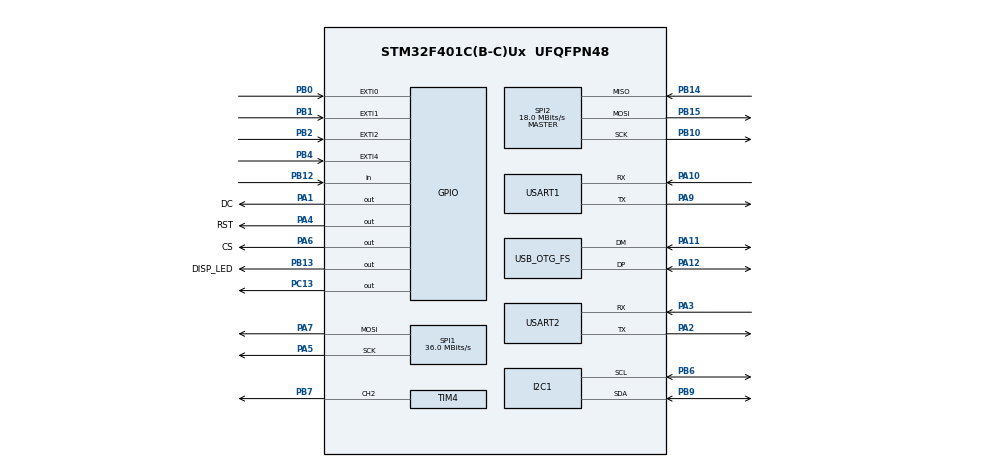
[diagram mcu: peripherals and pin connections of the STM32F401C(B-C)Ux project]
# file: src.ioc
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Dma.Request0=TIM4_CH2
Dma.TIM4_CH2.0.Direction=DMA_MEMORY_TO_PERIPH
Dma.TIM4_CH2.0.FIFOMode=DMA_FIFOMODE_DISABLE
Dma.TIM4_CH2.0.Instance=DMA1_Stream3
Dma.TIM4_CH2.0.MemDataAlignment=DMA_MDATAALIGN_HALFWORD
Dma.TIM4_CH2.0.MemInc=DMA_MINC_ENABLE
Dma.TIM4_CH2.0.Mode=DMA_CIRCULAR
Dma.TIM4_CH2.0.PeriphDataAlignment=DMA_PDATAALIGN_HALFWORD
Dma.TIM4_CH2.0.PeriphInc=DMA_PINC_DISABLE
Dma.TIM4_CH2.0.Priority=DMA_PRIORITY_LOW
Mcu.Family=STM32F4
Mcu.Name=STM32F401C(B-C)Ux
Mcu.Package=UFQFPN48
NVIC.DMA1_Stream3_IRQn=true\:2\:0\:true\:false\:true\:false\:true\:true
NVIC.EXTI0_IRQn=true\:0\:0\:false\:false\:true\:true\:true\:true
NVIC.EXTI1_IRQn=true\:0\:0\:false\:false\:true\:true\:true\:true
NVIC.EXTI2_IRQn=true\:0\:0\:false\:false\:true\:true\:true\:true
NVIC.EXTI4_IRQn=true\:0\:0\:false\:false\:true\:true\:true\:true
NVIC.OTG_FS_IRQn=true\:0\:0\:false\:false\:true\:false\:true\:true
NVIC.PriorityGroup=NVIC_PRIORITYGROUP_4
PA1.GPIO_Label=DC
PA1.GPIO_Speed=GPIO_SPEED_FREQ_HIGH
PA1.Signal=GPIO_Output
PA10.Mode=Asynchronous
PA10.Signal=USART1_RX
PA11.Mode=Device_Only
PA11.Signal=USB_OTG_FS_DM
PA12.Mode=Device_Only
PA12.Signal=USB_OTG_FS_DP
PA13.Mode=Trace_Asynchronous_SW
PA13.Signal=SYS_JTMS-SWDIO
PA14.Mode=Trace_Asynchronous_SW
PA14.Signal=SYS_JTCK-SWCLK
PA2.Mode=Asynchronous
PA2.Signal=USART2_TX
PA3.Mode=Asynchronous
PA3.Signal=USART2_RX
PA4.GPIO_Label=RST
PA4.GPIO_Speed=GPIO_SPEED_FREQ_HIGH
PA4.Signal=GPIO_Output
PA5.Mode=TX_Only_Simplex_Unidirect_Master
PA5.Signal=SPI1_SCK
PA6.GPIO_Label=CS
PA6.GPIO_Speed=GPIO_SPEED_FREQ_HIGH
PA6.Signal=GPIO_Output
PA7.Mode=TX_Only_Simplex_Unidirect_Master
PA7.Signal=SPI1_MOSI
PA9.Mode=Asynchronous
PA9.Signal=USART1_TX
PB0.GPIO_ModeDefaultEXTI=GPIO_MODE_IT_RISING_FALLING
PB0.GPIO_PuPd=GPIO_PULLDOWN
PB0.Signal=GPXTI0
PB1.GPIO_ModeDefaultEXTI=GPIO_MODE_IT_RISING_FALLING
PB1.GPIO_PuPd=GPIO_PULLDOWN
PB1.Signal=GPXTI1
PB10.Mode=Full_Duplex_Master
PB10.Signal=SPI2_SCK
PB12.GPIO_PuPd=GPIO_PULLDOWN
PB12.Signal=GPIO_Input
PB13.GPIO_Label=DISP_LED
PB13.GPIO_PuPd=GPIO_PULLDOWN
PB13.PinState=GPIO_PIN_SET
PB13.Signal=GPIO_Output
PB14.Mode=Full_Duplex_Master
PB14.Signal=SPI2_MISO
PB15.Mode=Full_Duplex_Master
PB15.Signal=SPI2_MOSI
PB2.GPIO_ModeDefaultEXTI=GPIO_MODE_IT_RISING_FALLING
PB2.GPIO_PuPd=GPIO_PULLDOWN
PB2.Signal=GPXTI2
PB3.Mode=Trace_Asynchronous_SW
PB3.Signal=SYS_JTDO-SWO
PB4.GPIO_ModeDefaultEXTI=GPIO_MODE_IT_RISING_FALLING
PB4.GPIO_PuPd=GPIO_PULLDOWN
PB4.Signal=GPXTI4
PB6.Mode=I2C
PB6.Signal=I2C1_SCL
PB7.GPIO_Speed=GPIO_SPEED_FREQ_LOW
PB7.Signal=S_TIM4_CH2
PB9.Mode=I2C
PB9.Signal=I2C1_SDA
PC13-ANTI_TAMP.GPIO_PuPd=GPIO_PULLUP
PC13-ANTI_TAMP.PinState=GPIO_PIN_SET
PC13-ANTI_TAMP.Signal=GPIO_Output
PC14-OSC32_IN.Mode=LSE-External-Oscillator
PC14-OSC32_IN.Signal=RCC_OSC32_IN
PC15-OSC32_OUT.Mode=LSE-External-Oscillator
PC15-OSC32_OUT.Signal=RCC_OSC32_OUT
PH0\ -\ OSC_IN.Mode=HSE-External-Oscillator
PH0\ -\ OSC_IN.Signal=RCC_OSC_IN
PH1\ -\ OSC_OUT.Mode=HSE-External-Oscillator
PH1\ -\ OSC_OUT.Signal=RCC_OSC_OUT
ProjectManager.HeapSize=0x400
ProjectManager.StackSize=0x800
ProjectManager.TargetToolchain=STM32CubeIDE
RCC.48MHZClocksFreq_Value=48000000
RCC.AHBFreq_Value=72000000
RCC.APB1CLKDivider=RCC_HCLK_DIV2
RCC.APB1Freq_Value=36000000
RCC.APB1TimFreq_Value=72000000
RCC.APB2Freq_Value=72000000
RCC.APB2TimFreq_Value=72000000
RCC.CortexFreq_Value=72000000
RCC.HCLKFreq_Value=72000000
RCC.HSE_VALUE=25000000
RCC.HSI_VALUE=16000000
RCC.PLLM=25
RCC.PLLN=144
RCC.PLLQ=3
RCC.SYSCLKFreq_VALUE=72000000
RCC.SYSCLKSource=RCC_SYSCLKSOURCE_PLLCLK
RCC.VCOOutputFreq_Value=144000000
SH.S_TIM4_CH2.0=TIM4_CH2,PWM Generation2 CH2
SPI1.BaudRatePrescaler=SPI_BAUDRATEPRESCALER_2
SPI1.CalculateBaudRate=36.0 MBits/s
SPI1.Direction=SPI_DIRECTION_2LINES
SPI1.Mode=SPI_MODE_MASTER
SPI1.VirtualType=VM_MASTER
SPI2.BaudRatePrescaler=SPI_BAUDRATEPRESCALER_2
SPI2.CalculateBaudRate=18.0 MBits/s
SPI2.Direction=SPI_DIRECTION_2LINES
SPI2.Mode=SPI_MODE_MASTER
SPI2.VirtualType=VM_MASTER
TIM4.Channel-PWM\ Generation2\ CH2=TIM_CHANNEL_2
TIM4.Period=89
USART1.VirtualMode=VM_ASYNC
USART2.VirtualMode=VM_ASYNC
USB_DEVICE.APP_RX_DATA_SIZE=256
USB_DEVICE.APP_TX_DATA_SIZE=256
USB_DEVICE.CLASS_NAME_FS=CDC
USB_DEVICE.VirtualMode=Cdc
USB_DEVICE.VirtualModeFS=Cdc_FS
USB_OTG_FS.VirtualMode=Device_Only
VP_CRC_VS_CRC.Mode=CRC_Activate
VP_USB_DEVICE_VS_USB_DEVICE_CDC_FS.Mode=CDC_FS
board=custom

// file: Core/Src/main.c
/* USER CODE BEGIN Header */
/**
 ******************************************************************************
 * @file           : main.c
 * @brief          : Main program body
 ******************************************************************************
 * @attention
 *
 * Copyright (c) 2022 STMicroelectronics.
 * All rights reserved.
 *
 * This software is licensed under terms that can be found in the LICENSE file
 * in the root directory of this software component.
 * If no LICENSE file comes with this software, it is provided AS-IS.
 *
 ******************************************************************************
 */
/* USER CODE END Header */
#include "main.h"
#include "crc.h"
#include "dma.h"
#include "gpio.h"
#include "i2c.h"
#include "spi.h"
#include "tim.h"
#include "usart.h"
#include "usb_device.h"

/* USER CODE BEGIN Includes */
#include "menu.h"
/* USER CODE END Includes */

void
SystemClock_Config(void);

int
main(void)
{

  /* MCU Configuration--------------------------------------------------------*/

  /* Reset of all peripherals, Initializes the Flash interface and the Systick.
   */
  HAL_Init();

  /* Configure the system clock */
  SystemClock_Config();

  /* Initialize all configured peripherals */
  MX_GPIO_Init();
  MX_CRC_Init();
  MX_I2C1_Init();
  MX_SPI1_Init();
  MX_SPI2_Init();
  MX_TIM4_Init();
  MX_USART1_UART_Init();
  MX_DMA_Init();
  MX_USB_DEVICE_Init();
  MX_USART2_UART_Init();
  /* USER CODE BEGIN 2 */
  Menu_Init();
  /* USER CODE END 2 */

  /* Infinite loop */
  /* USER CODE BEGIN WHILE */
  while (1) {
Menu();
   // HAL_IWDG_Refresh(&hiwdg);

    /* USER CODE END WHILE */

  }
}

void
SystemClock_Config(void)
{
  RCC_OscInitTypeDef RCC_OscInitStruct = { 0 };
  RCC_ClkInitTypeDef RCC_ClkInitStruct = { 0 };

  /** Configure the main internal regulator output voltage
   */
  __HAL_RCC_PWR_CLK_ENABLE();
  __HAL_PWR_VOLTAGESCALING_CONFIG(PWR_REGULATOR_VOLTAGE_SCALE2);

  /** Initializes the RCC Oscillators according to the specified parameters
  * in the RCC_OscInitTypeDef structure.
  */
  RCC_OscInitStruct.OscillatorType = RCC_OSCILLATORTYPE_HSE;
  RCC_OscInitStruct.HSEState = RCC_HSE_ON;
  RCC_OscInitStruct.PLL.PLLState = RCC_PLL_ON;
  RCC_OscInitStruct.PLL.PLLSource = RCC_PLLSOURCE_HSE;
  RCC_OscInitStruct.PLL.PLLM = 25;
  RCC_OscInitStruct.PLL.PLLN = 144;
  RCC_OscInitStruct.PLL.PLLP = RCC_PLLP_DIV2;
  RCC_OscInitStruct.PLL.PLLQ = 3;
  if (HAL_RCC_OscConfig(&RCC_OscInitStruct) != HAL_OK) {
    Error_Handler();
  }

  /** Initializes the CPU, AHB and APB buses clocks
   */
  RCC_ClkInitStruct.ClockType = RCC_CLOCKTYPE_HCLK | RCC_CLOCKTYPE_SYSCLK |
                                RCC_CLOCKTYPE_PCLK1 | RCC_CLOCKTYPE_PCLK2;
  RCC_ClkInitStruct.SYSCLKSource = RCC_SYSCLKSOURCE_PLLCLK;
  RCC_ClkInitStruct.AHBCLKDivider = RCC_SYSCLK_DIV1;
  RCC_ClkInitStruct.APB1CLKDivider = RCC_HCLK_DIV2;
  RCC_ClkInitStruct.APB2CLKDivider = RCC_HCLK_DIV1;

  if (HAL_RCC_ClockConfig(&RCC_ClkInitStruct, FLASH_LATENCY_2) != HAL_OK) {
    Error_Handler();
  }
}

void
Error_Handler(void)
{
  __disable_irq();
  while (1) {
  }
}

#ifdef USE_FULL_ASSERT
/**
 * @brief  Reports the name of the source file and the source line number
 *         where the assert_param error has occurred.
 * @param  file: pointer to the source file name
 * @param  line: assert_param error line source number
 * @retval None
 */
void
assert_failed(uint8_t* file, uint32_t line)
{
  /* USER CODE BEGIN 6 */
  /* User can add his own implementation to report the file name and line
     number,
     ex: printf("Wrong parameters value: file %s on line %d\r\n", file, line) */
  /* USER CODE END 6 */
}
#endif /* USE_FULL_ASSERT */
